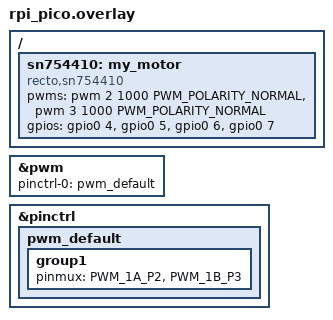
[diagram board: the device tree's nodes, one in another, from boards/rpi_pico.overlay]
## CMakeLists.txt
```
# Minimum CMake required version
cmake_minimum_required( VERSION 3.20.0 )

set(ZEPHYR_EXTRA_MODULES "${CMAKE_SOURCE_DIR}/drivers/recto_sn754410")
find_package(Zephyr REQUIRED HINTS $ENV{ZEPHYR_BASE})

# Project and source files
project(demo)
target_sources(app PRIVATE src/main.c)
```

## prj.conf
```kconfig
CONFIG_GPIO=y
CONFIG_PWM=y
CONFIG_RECTO_SN754410=y

#CONFIG_PRINTK=y
#CONFIG_CONSOLE=y
#CONFIG_STDOUT_CONSOLE=y
```

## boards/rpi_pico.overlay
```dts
/*
 * motor controller chip sn754410 requires 2 pwm and 4 gpio pins
 *
 * example overlay for rpi_pico board
 *   pwm1 - gpio 2
 *   pwm2 - gpio 3
 *   in1  - gpio 4
 *   in2  - gpio 5
 *   in3  - gpio 6
 *   in4  - gpio 7
 */

/ {
 
    sn754410: my_motor{
        compatible = "recto,sn754410";
        pwms = <&pwm 2 1000 PWM_POLARITY_NORMAL>, <&pwm 3 1000 PWM_POLARITY_NORMAL>;
        gpios = <&gpio0 4 GPIO_ACTIVE_HIGH>, <&gpio0 5 GPIO_ACTIVE_HIGH>, <&gpio0 6 GPIO_ACTIVE_HIGH>, <&gpio0 7 GPIO_ACTIVE_HIGH>;

        /*zephyr,deferred-init;*/
  
    };
};

/* enable pwm driver and configure pin control */
&pwm {
    status = "okay";
    pinctrl-0 = <&pwm_default>;
    pinctrl-names = "default";
};

/* define pinmux for group for pwms */
&pinctrl {
    pwm_default: pwm_default{
        group1 {
            pinmux = <PWM_1A_P2>, <PWM_1B_P3>;
        };
    };
};
```

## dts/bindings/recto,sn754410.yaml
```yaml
# binding description
description: Led conencted to a pin for multipurpose

# binding name (this is the one will be used in the device tree file)
compatible: "recto,sn754410"

#child-binding:
  # properties our node will have, in our case there is just one called gpios
  # which will be mandatory and their values are in a multi type array
properties:

  gpios:
    type: phandle-array
    required: true
    description: The GPIO pin connected to a simple led.
    
  pwms:
    type: phandle-array
    required: true
    description: The GPIO pin connected to a simple led.
```

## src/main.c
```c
/*
 * demo for motor controller sn754410 
 *
 * function call
 *
 *   motors_speed(motor device,
                  motor number, (1 or 2)
                  percent of speed (single digit i.e. 2 = 50%, 5 = 20 %_
                  )
                  
    motors_clockwise(motor device, motor number (1 or 2), true or false)
    
    motors_stop(motor device, motor number (1 or 2))
 */             

#include <zephyr/kernel.h>
#include <zephyr/drivers/gpio.h>
#include <zephyr/drivers/pwm.h>
#include "recto_sn754410.h"

const struct device *motors = DEVICE_DT_GET( DT_NODELABEL(sn754410) ); 

int main(void)
{   

   if(!device_is_ready(motors)){
     printk("failed");
     return 0;}

  while(1){
  
    motors_speed(motors, 1, 2);         // motor 1 stop
    motors_speed(motors, 2, 2);         // motor 2 50% speed
    motors_clockwise(motors, 1, true);  // motor 1 clockwise
    motors_clockwise(motors, 2, false); // moto2 2 counter clockwise
    k_msleep(2000);

    motors_speed(motors, 1, 5); // full speed 100%
    motors_speed(motors, 2, 6);
    motors_clockwise(motors, 1, false);
    motors_clockwise(motors, 2, true);
    k_msleep(2000);
    
    motors_stop(motors, 1); // motor 1 stop
    motors_stop(motors, 2); // motor 2 stop
    k_msleep(2000);
  }
	return 0;
}
```
